# PIC32MM0064GPM036 device description
Architecture: MIPS; Family: PIC32MM1387; Series: PIC32MM
Registers are 32-bit, read-write, no defined reset value unless marked. A register's access mark holds for its fields unless they carry their own. Offsets are from the block's base; [hi:lo] are bit positions; {n}, {i} and the like mark numbered series; 'fields as' and 'values as' point back to an identical list.

## CRU
Instances: CRU 0x1f802680 in periph0
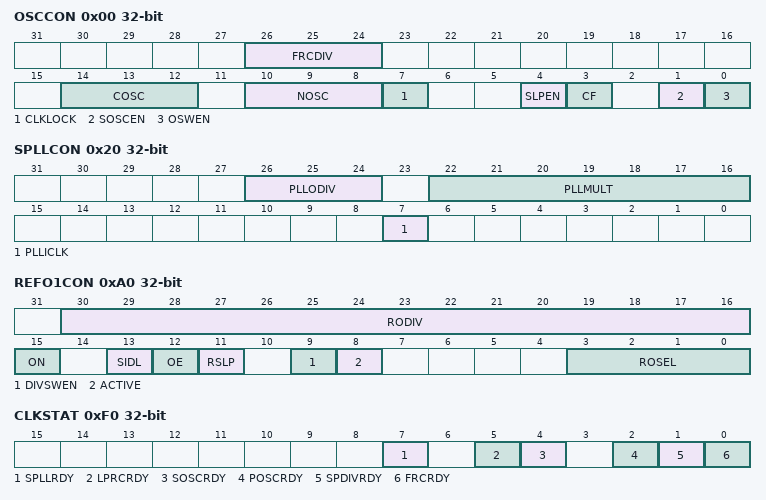
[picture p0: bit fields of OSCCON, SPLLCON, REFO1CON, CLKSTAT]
0x00 OSCCON — Oscillator Control Register
  [26:24] FRCDIV — Internal Fast RC Oscillator Clock Divider bits
    7=DIV_256 (FRC divided by 256); 6=DIV_64 (FRC divided by 64); 5=DIV_32 (FRC divided by 32); 4=DIV_16 (FRC divided by 16); 3=DIV_8 (FRC divided by 8); 2=DIV_4 (FRC divided by 4); 1=DIV_2 (FRC divided by 2); 0=DIV_1 (FRC divided by 1 (default setting))
  [14:12] COSC — Current Oscillator Selection bits
    5=LPRC (Internal Low-Power RC (LPRC) Oscillator); 4=SOSC (Secondary Oscillator (SOSC)); 2=PRI (Primary Oscillator (POSC) (HS or EC)); 1=PRIPLL (System PLL (SPLL)); 0=FRCDIV (Internal Fast RC (FRC) Oscillator divided by FRCDIV bits (FRCDIV))
  [10:8] NOSC — New Oscillator Selection bits
    values as COSC
  [7] CLKLOCK — Clock Selection Lock Enable bit
    1=Clock and PLL selections are locked; 0=Clock and PLL selections are not locked and may be modified
  [4] SLPEN — Sleep Mode Enable bit
    1=Device will enter Sleep mode when a WAIT instruction is executed; 0=Device will enter Idle mode when a WAIT instruction is executed
  [3] CF — Clock Fail Detect bit
    1=FSCM has detected a clock failure; 0=No clock failure has been detected
  [1] SOSCEN — Secondary Oscillator Enable bit
    1=ON (Enable Secondary Oscillator); 0=OFF (Disable Secondary Oscillator)
  [0] OSWEN — Oscillator Switch Enable bit
    1=Initiate an oscillator switch to selection specified by NOSC bits; 0=Oscillator switch is complete
0x20 SPLLCON — System PLL Control Register
  [26:24] PLLODIV — System PLL Output Clock Divider bits
    7=DIV_256 (PLL Divide by 256); 6=DIV_64 (PLL Divide by 64); 5=DIV_32 (PLL Divide by 32); 4=DIV_16 (PLL Divide by 16); 3=DIV_8 (PLL Divide by 8); 2=DIV_4 (PLL Divide by 4); 1=DIV_2 (PLL Divide by 2); 0=DIV_1 (PLL Divide by 1)
  [22:16] PLLMULT — System PLL Multiplier bits
    6=MUL_24 (Multiply by 24); 5=MUL_12 (Multiply by 12); 4=MUL_8 (Multiply by 8); 3=MUL_6 (Multiply by 6); 2=MUL_4 (Multiply by 4); 1=MUL_3 (Multiply by 3); 0=MUL_2 (Multiply by 2)
  [7] PLLICLK — System PLL Input Clock Source bit
    1=FRC is selected as the input to the System PLL; 0=POSC is selected as the input to the System PLL
0xA0 REFO1CON — Reference Oscillator Control Register
  [30:16] RODIV
    0=NO_DIV (RReference Clock output is same as source clock); 1=DIV_2 (Reference Clock output is source clock divided by 2); 2=DIV_4 (Reference Clock output is source clock divided by 4); 0x7fff=DIV_65534 (Reference Clock output is source clock divided by 65534)
  [15] ON — Output Enable bit
    1=Reference Oscillator Module enabled; 0=Reference Oscillator Module disabled
  [13] SIDL — Peripheral Stop in Idle Mode bit
    1=Discontinue module operation when the device enters Idle mode; 0=Continue module operation in Idle mode
  [12] OE — Reference Clock Output Enable bit
    1=Reference clock is driven out on REFCLKOx pin; 0=Reference clock is not driven out on REFCLKOx pin
  [11] RSLP — Reference Oscillator Module Run in Sleep bit
    1=Reference Oscillator Module output continues to run in Sleep; 0=Reference Oscillator Module output is disabled in Sleep
  [9] DIVSWEN — Divider Switch Enable bit
    1=Divider switch is in progress; 0=Divider switch is complete
  [8] ACTIVE — Reference Clock Request Status bit
    1=Reference clock request is active; 0=Reference clock request is not active
  [3:0] ROSEL — Reference Clock Source Select bits
    9=REFCLKI; 7=Fvco (System PLL VCO output); 5=SOSC; 4=LPRC; 3=FRC; 2=POSC; 0=SYSCLK
0xB0 REFO1TRIM — Reference Oscillator Trim Register
  [31:23] ROTRIM — Reference Oscillator Trim bits
    0x1ff=511/512 divisor added to RODIV value; 0x1fe=510/512 divisor added to RODIV value; 0x1fd=509/512 divisor added to RODIV value; 0x1fc=508/512 divisor added to RODIV value; 0x1fb=507/512 divisor added to RODIV value; 0x1fa=506/512 divisor added to RODIV value; 0x1f9=505/512 divisor added to RODIV value; 0x1f8=504/512 divisor added to RODIV value; 0x1f7=503/512 divisor added to RODIV value; 0x1f6=502/512 divisor added to RODIV value; 0x1f5=501/512 divisor added to RODIV value; 0x1f4=500/512 divisor added to RODIV value; 0x1f3=499/512 divisor added to RODIV value; 0x1f2=498/512 divisor added to RODIV value; 0x1f1=497/512 divisor added to RODIV value; 0x1f0=496/512 divisor added to RODIV value; 0x1ef=495/512 divisor added to RODIV value; 0x1ee=494/512 divisor added to RODIV value; 0x1ed=493/512 divisor added to RODIV value; 0x1ec=492/512 divisor added to RODIV value; 0x1eb=491/512 divisor added to RODIV value; 0x1ea=490/512 divisor added to RODIV value; 0x1e9=489/512 divisor added to RODIV value; 0x1e8=488/512 divisor added to RODIV value; 0x1e7=487/512 divisor added to RODIV value; 0x1e6=486/512 divisor added to RODIV value; 0x1e5=485/512 divisor added to RODIV value; 0x1e4=484/512 divisor added to RODIV value; 0x1e3=483/512 divisor added to RODIV value; 0x1e2=482/512 divisor added to RODIV value; 0x1e1=481/512 divisor added to RODIV value; 0x1e0=480/512 divisor added to RODIV value; 0x1df=479/512 divisor added to RODIV value; 0x1de=478/512 divisor added to RODIV value; 0x1dd=477/512 divisor added to RODIV value; 0x1dc=476/512 divisor added to RODIV value; 0x1db=475/512 divisor added to RODIV value; 0x1da=474/512 divisor added to RODIV value; 0x1d9=473/512 divisor added to RODIV value; 0x1d8=472/512 divisor added to RODIV value; 0x1d7=471/512 divisor added to RODIV value; 0x1d6=470/512 divisor added to RODIV value; 0x1d5=469/512 divisor added to RODIV value; 0x1d4=468/512 divisor added to RODIV value; 0x1d3=467/512 divisor added to RODIV value; 0x1d2=466/512 divisor added to RODIV value; 0x1d1=465/512 divisor added to RODIV value; 0x1d0=464/512 divisor added to RODIV value; 0x1cf=463/512 divisor added to RODIV value; 0x1ce=462/512 divisor added to RODIV value; 0x1cd=461/512 divisor added to RODIV value; 0x1cc=460/512 divisor added to RODIV value; 0x1cb=459/512 divisor added to RODIV value; 0x1ca=458/512 divisor added to RODIV value; 0x1c9=457/512 divisor added to RODIV value; 0x1c8=456/512 divisor added to RODIV value; 0x1c7=455/512 divisor added to RODIV value; 0x1c6=454/512 divisor added to RODIV value; 0x1c5=453/512 divisor added to RODIV value; 0x1c4=452/512 divisor added to RODIV value; 0x1c3=451/512 divisor added to RODIV value; 0x1c2=450/512 divisor added to RODIV value; 0x1c1=449/512 divisor added to RODIV value; 0x1c0=448/512 divisor added to RODIV value; 0x1bf=447/512 divisor added to RODIV value; 0x1be=446/512 divisor added to RODIV value; 0x1bd=445/512 divisor added to RODIV value; 0x1bc=444/512 divisor added to RODIV value; 0x1bb=443/512 divisor added to RODIV value; 0x1ba=442/512 divisor added to RODIV value; 0x1b9=441/512 divisor added to RODIV value; 0x1b8=440/512 divisor added to RODIV value; 0x1b7=439/512 divisor added to RODIV value; 0x1b6=438/512 divisor added to RODIV value; 0x1b5=437/512 divisor added to RODIV value; 0x1b4=436/512 divisor added to RODIV value; 0x1b3=435/512 divisor added to RODIV value; 0x1b2=434/512 divisor added to RODIV value; 0x1b1=433/512 divisor added to RODIV value; 0x1b0=432/512 divisor added to RODIV value; 0x1af=431/512 divisor added to RODIV value; 0x1ae=430/512 divisor added to RODIV value; 0x1ad=429/512 divisor added to RODIV value; 0x1ac=428/512 divisor added to RODIV value; 0x1ab=427/512 divisor added to RODIV value; 0x1aa=426/512 divisor added to RODIV value; 0x1a9=425/512 divisor added to RODIV value; 0x1a8=424/512 divisor added to RODIV value; 0x1a7=423/512 divisor added to RODIV value; 0x1a6=422/512 divisor added to RODIV value; 0x1a5=421/512 divisor added to RODIV value; 0x1a4=420/512 divisor added to RODIV value; 0x1a3=419/512 divisor added to RODIV value; 0x1a2=418/512 divisor added to RODIV value; 0x1a1=417/512 divisor added to RODIV value; 0x1a0=416/512 divisor added to RODIV value; 0x19f=415/512 divisor added to RODIV value; 0x19e=414/512 divisor added to RODIV value; 0x19d=413/512 divisor added to RODIV value; 0x19c=412/512 divisor added to RODIV value; 0x19b=411/512 divisor added to RODIV value; 0x19a=410/512 divisor added to RODIV value; 0x199=409/512 divisor added to RODIV value; 0x198=408/512 divisor added to RODIV value; 0x197=407/512 divisor added to RODIV value; 0x196=406/512 divisor added to RODIV value; 0x195=405/512 divisor added to RODIV value; 0x194=404/512 divisor added to RODIV value; 0x193=403/512 divisor added to RODIV value; 0x192=402/512 divisor added to RODIV value; 0x191=401/512 divisor added to RODIV value; 0x190=400/512 divisor added to RODIV value; 0x18f=399/512 divisor added to RODIV value; 0x18e=398/512 divisor added to RODIV value; 0x18d=397/512 divisor added to RODIV value; 0x18c=396/512 divisor added to RODIV value; 0x18b=395/512 divisor added to RODIV value; 0x18a=394/512 divisor added to RODIV value; 0x189=393/512 divisor added to RODIV value; 0x188=392/512 divisor added to RODIV value; 0x187=391/512 divisor added to RODIV value; 0x186=390/512 divisor added to RODIV value; 0x185=389/512 divisor added to RODIV value; 0x184=388/512 divisor added to RODIV value; 0x183=387/512 divisor added to RODIV value; 0x182=386/512 divisor added to RODIV value; 0x181=385/512 divisor added to RODIV value; 0x180=384/512 divisor added to RODIV value; 0x17f=383/512 divisor added to RODIV value; 0x17e=382/512 divisor added to RODIV value; 0x17d=381/512 divisor added to RODIV value; 0x17c=380/512 divisor added to RODIV value; 0x17b=379/512 divisor added to RODIV value; 0x17a=378/512 divisor added to RODIV value; 0x179=377/512 divisor added to RODIV value; 0x178=376/512 divisor added to RODIV value; 0x177=375/512 divisor added to RODIV value; 0x176=374/512 divisor added to RODIV value; 0x175=373/512 divisor added to RODIV value; 0x174=372/512 divisor added to RODIV value; 0x173=371/512 divisor added to RODIV value; 0x172=370/512 divisor added to RODIV value; 0x171=369/512 divisor added to RODIV value; 0x170=368/512 divisor added to RODIV value; 0x16f=367/512 divisor added to RODIV value; 0x16e=366/512 divisor added to RODIV value; 0x16d=365/512 divisor added to RODIV value; 0x16c=364/512 divisor added to RODIV value; 0x16b=363/512 divisor added to RODIV value; 0x16a=362/512 divisor added to RODIV value; 0x169=361/512 divisor added to RODIV value; 0x168=360/512 divisor added to RODIV value; 0x167=359/512 divisor added to RODIV value; 0x166=358/512 divisor added to RODIV value; 0x165=357/512 divisor added to RODIV value; 0x164=356/512 divisor added to RODIV value; 0x163=355/512 divisor added to RODIV value; 0x162=354/512 divisor added to RODIV value; 0x161=353/512 divisor added to RODIV value; 0x160=352/512 divisor added to RODIV value; 0x15f=351/512 divisor added to RODIV value; 0x15e=350/512 divisor added to RODIV value; 0x15d=349/512 divisor added to RODIV value; 0x15c=348/512 divisor added to RODIV value; 0x15b=347/512 divisor added to RODIV value; 0x15a=346/512 divisor added to RODIV value; 0x159=345/512 divisor added to RODIV value; 0x158=344/512 divisor added to RODIV value; 0x157=343/512 divisor added to RODIV value; 0x156=342/512 divisor added to RODIV value; 0x155=341/512 divisor added to RODIV value; 0x154=340/512 divisor added to RODIV value; 0x153=339/512 divisor added to RODIV value; 0x152=338/512 divisor added to RODIV value; 0x151=337/512 divisor added to RODIV value; 0x150=336/512 divisor added to RODIV value; 0x14f=335/512 divisor added to RODIV value; 0x14e=334/512 divisor added to RODIV value; 0x14d=333/512 divisor added to RODIV value; 0x14c=332/512 divisor added to RODIV value; 0x14b=331/512 divisor added to RODIV value; 0x14a=330/512 divisor added to RODIV value; 0x149=329/512 divisor added to RODIV value; 0x148=328/512 divisor added to RODIV value; 0x147=327/512 divisor added to RODIV value; 0x146=326/512 divisor added to RODIV value; 0x145=325/512 divisor added to RODIV value; 0x144=324/512 divisor added to RODIV value; 0x143=323/512 divisor added to RODIV value; 0x142=322/512 divisor added to RODIV value; 0x141=321/512 divisor added to RODIV value; 0x140=320/512 divisor added to RODIV value; 0x13f=319/512 divisor added to RODIV value; 0x13e=318/512 divisor added to RODIV value; 0x13d=317/512 divisor added to RODIV value; 0x13c=316/512 divisor added to RODIV value; 0x13b=315/512 divisor added to RODIV value; 0x13a=314/512 divisor added to RODIV value; 0x139=313/512 divisor added to RODIV value; 0x138=312/512 divisor added to RODIV value; 0x137=311/512 divisor added to RODIV value; 0x136=310/512 divisor added to RODIV value; 0x135=309/512 divisor added to RODIV value; 0x134=308/512 divisor added to RODIV value; 0x133=307/512 divisor added to RODIV value; 0x132=306/512 divisor added to RODIV value; 0x131=305/512 divisor added to RODIV value; 0x130=304/512 divisor added to RODIV value; 0x12f=303/512 divisor added to RODIV value; 0x12e=302/512 divisor added to RODIV value; 0x12d=301/512 divisor added to RODIV value; 0x12c=300/512 divisor added to RODIV value; 0x12b=299/512 divisor added to RODIV value; 0x12a=298/512 divisor added to RODIV value; 0x129=297/512 divisor added to RODIV value; 0x128=296/512 divisor added to RODIV value; 0x127=295/512 divisor added to RODIV value; 0x126=294/512 divisor added to RODIV value; 0x125=293/512 divisor added to RODIV value; 0x124=292/512 divisor added to RODIV value; 0x123=291/512 divisor added to RODIV value; 0x122=290/512 divisor added to RODIV value; 0x121=289/512 divisor added to RODIV value; 0x120=288/512 divisor added to RODIV value; 0x11f=287/512 divisor added to RODIV value; 0x11e=286/512 divisor added to RODIV value; 0x11d=285/512 divisor added to RODIV value; 0x11c=284/512 divisor added to RODIV value; 0x11b=283/512 divisor added to RODIV value; 0x11a=282/512 divisor added to RODIV value; 0x119=281/512 divisor added to RODIV value; 0x118=280/512 divisor added to RODIV value; 0x117=279/512 divisor added to RODIV value; 0x116=278/512 divisor added to RODIV value; 0x115=277/512 divisor added to RODIV value; 0x114=276/512 divisor added to RODIV value; 0x113=275/512 divisor added to RODIV value; 0x112=274/512 divisor added to RODIV value; 0x111=273/512 divisor added to RODIV value; 0x110=272/512 divisor added to RODIV value; 0x10f=271/512 divisor added to RODIV value; 0x10e=270/512 divisor added to RODIV value; 0x10d=269/512 divisor added to RODIV value; 0x10c=268/512 divisor added to RODIV value; 0x10b=267/512 divisor added to RODIV value; 0x10a=266/512 divisor added to RODIV value; 0x109=265/512 divisor added to RODIV value; 0x108=264/512 divisor added to RODIV value; 0x107=263/512 divisor added to RODIV value; 0x106=262/512 divisor added to RODIV value; 0x105=261/512 divisor added to RODIV value; 0x104=260/512 divisor added to RODIV value; 0x103=259/512 divisor added to RODIV value; 0x102=258/512 divisor added to RODIV value; 0x101=257/512 divisor added to RODIV value; 0x100=256/512 divisor added to RODIV value; {v}={v}/512 divisor added to RODIV value (v=1..255); 0=0 divisor added to RODIV value
0xF0 CLKSTAT — Oscillator Clock Status Register
  [7] SPLLRDY — System PLL (SPLL) Ready Status bit
    1=SPLL is ready; 0=SPLL is not ready
  [5] LPRCRDY — Low-Power RC (LPRC) Oscillator Ready Status bit
    1=LPRC is stable and ready; 0=LPRC is disabled or not operating
  [4] SOSCRDY — Secondary Oscillator (SOSC) Ready Status bit
    1=SOSC is stable and ready; 0=SOSC is disabled or not operating
  [2] POSCRDY — Primary Oscillator (POSC) Ready Status bit
    1=POSC is stable and ready; 0=POSC is disabled or not operating
  [1] SPDIVRDY — System PLL Ready Status bit
    1=Divided System PLL is ready; 0=Divided System PLL is not ready
  [0] FRCRDY — Fast RC (FRC) Oscillator Ready Status bit
    1=FRC is stable and ready; 0=FRC is disabled for not operating
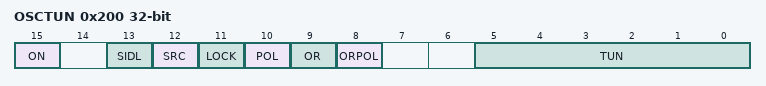
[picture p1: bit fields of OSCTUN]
0x200 OSCTUN — FRC Tuning Register
  [15] ON
  [13] SIDL
  [12] SRC
  [11] LOCK
  [10] POL
  [9] OR
  [8] ORPOL
  [5:0] TUN — FRC Oscillator Tuning bits
    32=Center frequency -1.5%; 0=Center frequency; Oscillator runs at nominal frequency (8 MHz); 31=Center frequency +1.453%
